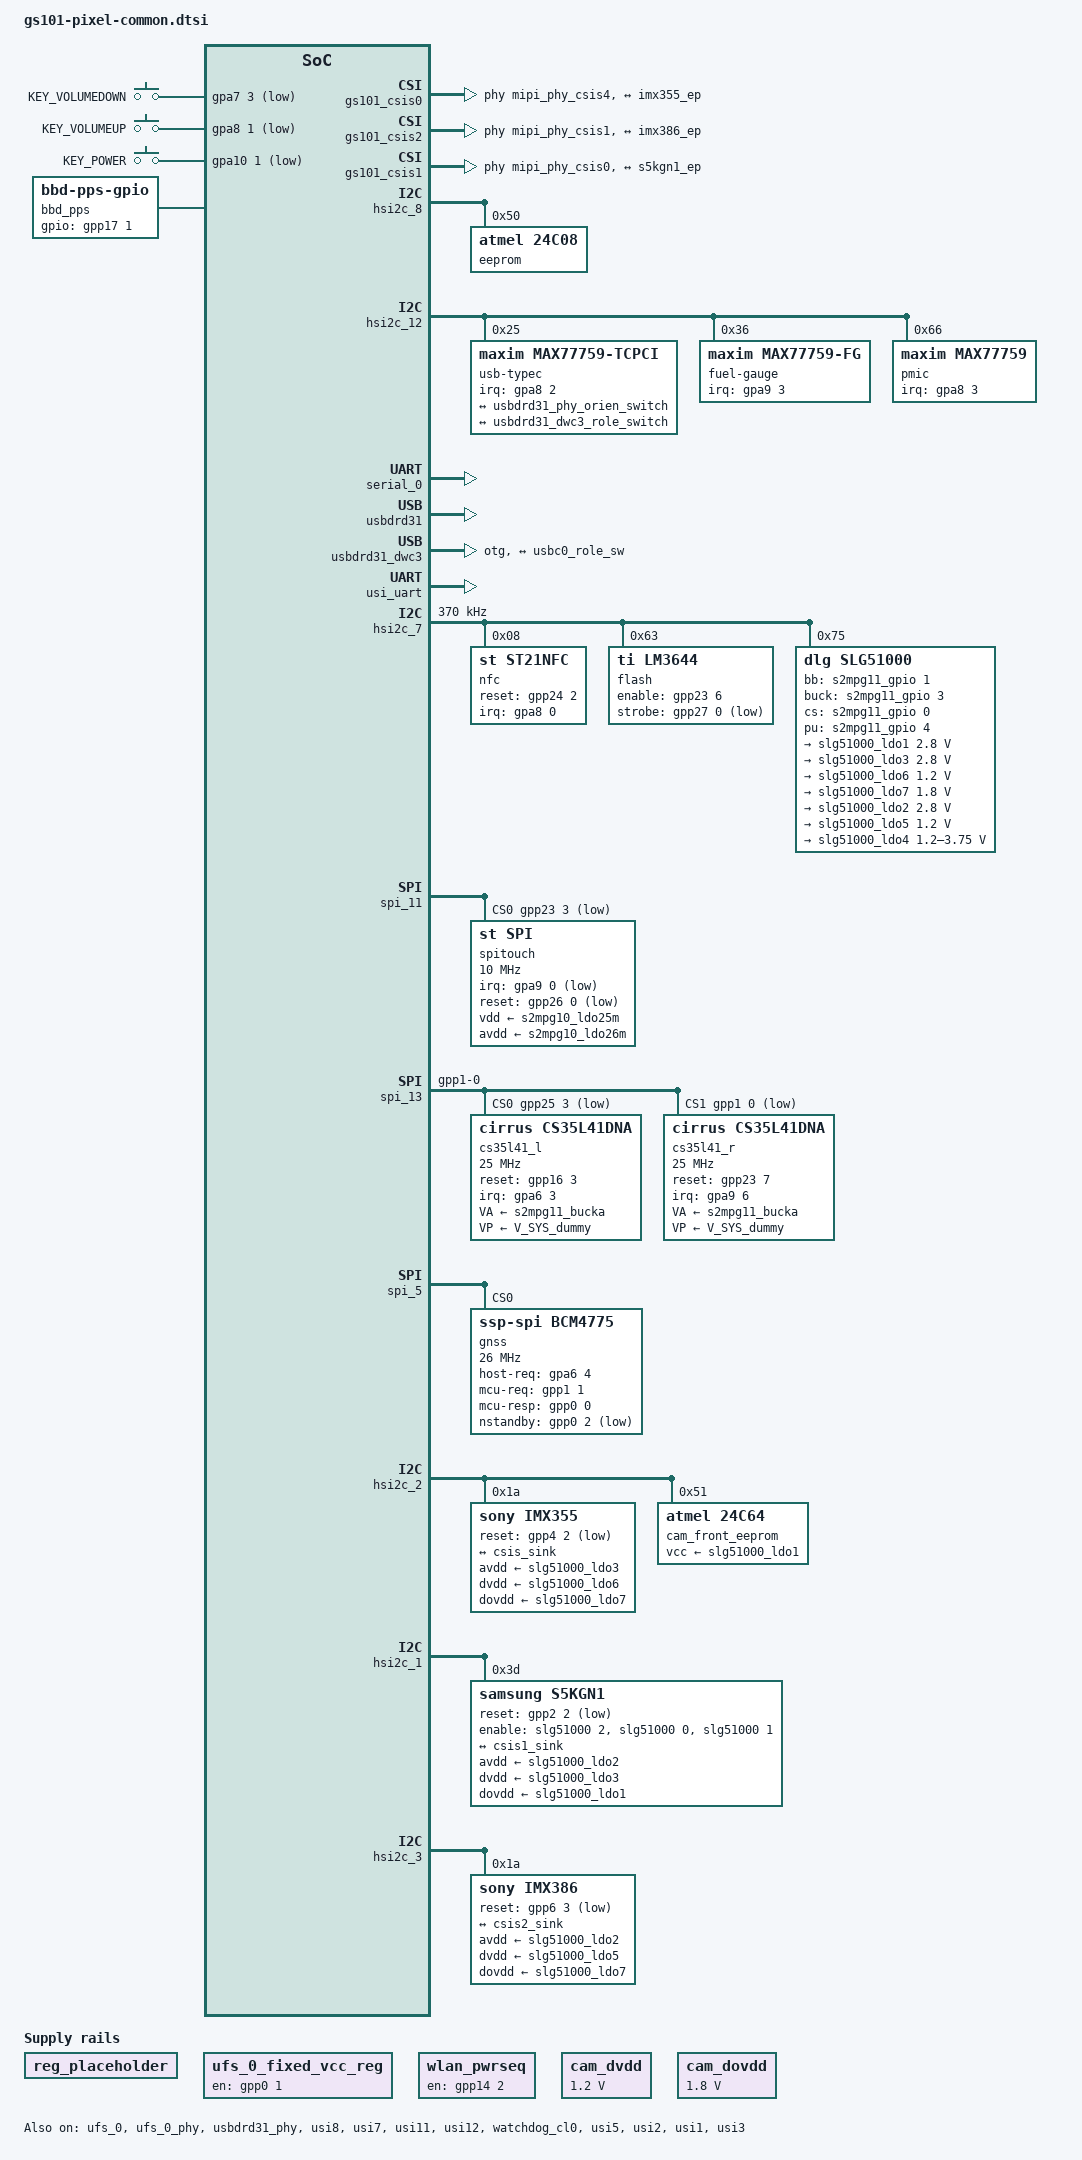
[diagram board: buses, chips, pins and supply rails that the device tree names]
// SPDX-License-Identifier: GPL-2.0-only
/*
 * Device Tree nodes common for all GS101-based Pixel
 *
 * Copyright 2021-2023 Google LLC
 * Copyright 2023 Linaro Ltd - <peter.griffin@linaro.org>
 */

/dts-v1/;

#include <dt-bindings/gpio/gpio.h>
#include <dt-bindings/input/input.h>
#include <dt-bindings/regulator/samsung,s2mpg10-regulator.h>
#include <dt-bindings/usb/pd.h>
#include "gs101-pinctrl.h"
#include "gs101.dtsi"
#include "gs101-audio.dtsi"
#include "gs101-cp-rmem.dtsi"
#include "gs101-cp-nodes.dtsi"
#include "gs101-cp-spi.dtsi"
#include <dt-bindings/media/video-interfaces.h>

/ {
	aliases {
		serial0 = &serial_0;
	};

	chosen {
		/* Bootloader expects bootargs specified otherwise it crashes */
		bootargs = "";
		stdout-path = &serial_0;

		/* Use display framebuffer as setup by bootloader */
		framebuffer0: framebuffer-0 {
			compatible = "simple-framebuffer";
			memory-region = <&cont_splash_mem>;
			vci-supply = <&s2mpg10_ldo22m>;
			vddi-supply = <&s2mpg11_bucka>;
			/* format properties to be added by actual board */
			status = "disabled";
		};
	};

	gpio-keys {
		compatible = "gpio-keys";
		pinctrl-0 = <&key_voldown>, <&key_volup>, <&key_power>;
		pinctrl-names = "default";

		button-vol-down {
			label = "KEY_VOLUMEDOWN";
			linux,code = <KEY_VOLUMEDOWN>;
			gpios = <&gpa7 3 GPIO_ACTIVE_LOW>;
			wakeup-source;
		};

		button-vol-up {
			label = "KEY_VOLUMEUP";
			linux,code = <KEY_VOLUMEUP>;
			gpios = <&gpa8 1 GPIO_ACTIVE_LOW>;
			wakeup-source;
		};

		button-power {
			label = "KEY_POWER";
			linux,code = <KEY_POWER>;
			gpios = <&gpa10 1 GPIO_ACTIVE_LOW>;
			wakeup-source;
		};
	};

	reboot-mode {
		compatible = "nvmem-reboot-mode";
		nvmem-cells = <&nvmem_reboot_mode>;
		nvmem-cell-names = "reboot-mode";
		mode-bootloader = <0x800000fc>;
		mode-charge = <0x8000000a>;
		mode-dm-verity-device-corrupted = <0x80000050>;
		mode-fastboot = <0x800000fa>;
		mode-reboot-ab-update = <0x80000052>;
		mode-recovery = <0x800000ff>;
		mode-rescue = <0x800000f9>;
		mode-shutdown-thermal = <0x80000051>;
		mode-shutdown-thermal-battery = <0x80000051>;
	};

	/* TODO: Remove this once PMIC is implemented  */
	reg_placeholder: regulator-0 {
		compatible = "regulator-fixed";
		regulator-name = "placeholder_reg";
	};

	/* TODO: Remove this once S2MPG11 slave PMIC is implemented  */
	ufs_0_fixed_vcc_reg: regulator-1 {
		compatible = "regulator-fixed";
		regulator-name = "ufs-vcc";
		gpio = <&gpp0 1 GPIO_ACTIVE_HIGH>;
		regulator-boot-on;
		enable-active-high;
	};

	/*
	 * WLAN power enable (BCM4389 on PCIe HSI2). The vendor "wl_reg_on"
	 * GPIO; drive it on so the endpoint is powered before the PCIe link
	 * trains. always-on because there is no bcmdhd driver to toggle it.
	 */
	wlan_pwrseq: regulator-wlan {
		compatible = "regulator-fixed";
		regulator-name = "wlan-en";
		gpio = <&gpp14 2 GPIO_ACTIVE_HIGH>;
		enable-active-high;
		regulator-always-on;
		regulator-boot-on;
	};

	/*
	 * Front camera (IMX355) digital/IO rails. On the vendor these are
	 * board rails that stay on; LWIS only toggles avdd (slg51000_ldo1).
	 * Modelled as always-on fixed regulators so the mainline imx355 driver
	 * (which requires avdd/dvdd/dovdd) can enable its bulk supplies.
	 * TODO(M1b): map to the real s2mpg rails feeding the sensor.
	 */
	cam_dvdd: regulator-cam-dvdd {
		compatible = "regulator-fixed";
		regulator-name = "cam-dvdd";
		regulator-min-microvolt = <1200000>;
		regulator-max-microvolt = <1200000>;
		regulator-always-on;
		regulator-boot-on;
	};

	cam_dovdd: regulator-cam-dovdd {
		compatible = "regulator-fixed";
		regulator-name = "cam-dovdd";
		regulator-min-microvolt = <1800000>;
		regulator-max-microvolt = <1800000>;
		regulator-always-on;
		regulator-boot-on;
	};

	/*
	 * Camera MIPI D/C-combo PHYs (samsung,mipi-phy-m0s4s4s4s4s4), one per
	 * CSIS link. Driven by phy-exynos-mipi-gs101; isolation via the gs101
	 * PMU syscon, reset via the CSIS sysreg. Consumed by the MIPI-CSIS
	 * receiver nodes (added with the CSIS driver, M-next). Addresses/reset
	 * bits from vendor gs101-isp.dtsi.
	 */
	sysreg_csis_reset: system-controller@1a420500 {
		compatible = "samsung,exynos-csis", "syscon";
		reg = <0x0 0x1A420500 0x8>;
	};

	mipi_phy_csis0: dcphy@1a4f1300 {
		compatible = "samsung,mipi-phy-m0s4s4s4s4s4";
		samsung,pmu-syscon = <&pmu_system_controller>;
		isolation = <0x3ebc>;
		samsung,reset-sysreg = <&sysreg_csis_reset>;
		reset = <0>;
		reg = <0x0 0x1A4F1300 0x500>;
		owner = <1>;
		#phy-cells = <1>;
	};

	mipi_phy_csis1: dcphy@1a4f1b00 {
		compatible = "samsung,mipi-phy-m0s4s4s4s4s4";
		samsung,pmu-syscon = <&pmu_system_controller>;
		isolation = <0x3ebc>;
		samsung,reset-sysreg = <&sysreg_csis_reset>;
		reset = <1>;
		reg = <0x0 0x1A4F1B00 0x500>;
		owner = <1>;
		#phy-cells = <1>;
	};

	mipi_phy_csis2: dcphy@1a4f2300 {
		compatible = "samsung,mipi-phy-m0s4s4s4s4s4";
		samsung,pmu-syscon = <&pmu_system_controller>;
		isolation = <0x3ebc>;
		samsung,reset-sysreg = <&sysreg_csis_reset>;
		reset = <2>;
		reg = <0x0 0x1A4F2300 0x300>;
		owner = <1>;
		#phy-cells = <1>;
	};

	mipi_phy_csis3: dcphy@1a4f2600 {
		compatible = "samsung,mipi-phy-m0s4s4s4s4s4";
		samsung,pmu-syscon = <&pmu_system_controller>;
		isolation = <0x3ebc>;
		samsung,reset-sysreg = <&sysreg_csis_reset>;
		reset = <3>;
		reg = <0x0 0x1A4F2600 0x300>;
		owner = <1>;
		#phy-cells = <1>;
	};

	/*
	 * dcphy4 is where the front IMX355 physically lands (proven 2026-09-18
	 * by probing every bank with the sensor streaming: only this one sees
	 * the HS clock). As a 4-lane receiver it uses the clock lane at 0x2B00
	 * and data lanes 0x2C00..0x2F00, i.e. the vendor DT's "csi4" (0x2B00,
	 * 0x300) plus "csi5" (0x2E00, 0x300) -- so the bank is 0x500 here and
	 * the separate csi5 node below is commented out (it would overlap).
	 */
	mipi_phy_csis4: dcphy@1a4f2b00 {
		compatible = "samsung,mipi-phy-m0s4s4s4s4s4";
		samsung,pmu-syscon = <&pmu_system_controller>;
		isolation = <0x3ebc>;
		samsung,reset-sysreg = <&sysreg_csis_reset>;
		reset = <4>;
		reg = <0x0 0x1A4F2B00 0x500>;	/* was 0x300 (vendor csi4 only) */
		owner = <1>;
		#phy-cells = <1>;
	};

/*	mipi_phy_csis5: dcphy@1a4f2e00 {	-- overlaps dcphy4's data lanes, see above
 *		compatible = "samsung,mipi-phy-m0s4s4s4s4s4";
 *		samsung,pmu-syscon = <&pmu_system_controller>;
 *		isolation = <0x3ebc>;
 *		samsung,reset-sysreg = <&sysreg_csis_reset>;
 *		reset = <5>;
 *		reg = <0x0 0x1A4F2E00 0x300>;
 *		owner = <1>;
 *		#phy-cells = <1>;
 *	};
 */

	mipi_phy_csis6: dcphy@1a4f3300 {
		compatible = "samsung,mipi-phy-m0s4s4s4s4s4";
		samsung,pmu-syscon = <&pmu_system_controller>;
		isolation = <0x3ebc>;
		samsung,reset-sysreg = <&sysreg_csis_reset>;
		reset = <6>;
		reg = <0x0 0x1A4F3300 0x300>;
		owner = <1>;
		#phy-cells = <1>;
	};

	mipi_phy_csis7: dcphy@1a4f3600 {
		compatible = "samsung,mipi-phy-m0s4s4s4s4s4";
		samsung,pmu-syscon = <&pmu_system_controller>;
		isolation = <0x3ebc>;
		samsung,reset-sysreg = <&sysreg_csis_reset>;
		reset = <7>;
		reg = <0x0 0x1A4F3600 0x300>;
		owner = <1>;
		#phy-cells = <1>;
	};

	/*
	 * MIPI-CSIS receivers (google,gs101-mipi-csis). Each gs101 CSIS link is
	 * separate hardware (link N = 0x1A440000 + N * 0x10000), so each is its
	 * own node/driver instance. They share the one CSIS write-DMA bank
	 * (0x1A4D0000, raw Bayer -> DRAM) but write through distinct virtual
	 * channels (google,csis-dma-vc). Register bases from vendor
	 * gs101-isp.dtsi (lwis_csi); the dcphys above are reached through the
	 * generic PHY framework, so the csis-phy bank is not mapped here.
	 *
	 * csis0: front camera IMX355 (4-lane) on link4 / dcphy4 / WDMA vc0.
	 * (Was link0 / dcphy0 until 2026-09-18 -- an unverified assumption;
	 * the sensor is wired to DCPHY4, see the dcphy4 node above.)
	 */
	gs101_csis0: mipi-csis@1a480000 {
		compatible = "google,gs101-mipi-csis";
		reg = <0x0 0x1A480000 0x1000>,   /* csis-link4 (was 0x1A440000 link0) */
		      <0x0 0x1A4D0000 0x10000>,  /* csis-dma (WDMA, shared) */
		      <0x0 0x1A4C0000 0x100>;    /* csis-ebuf (elastic buffer, shared) */
		reg-names = "csis-link4", "csis-dma", "csis-ebuf";
		/*
		 * reg[0] = link bank; IRQs are the WDMA frame-done for this vc
		 * (IRQ_CSIS_DMA0_CSIS = SPI 302) + the link IRQ (IRQ_CSIS4_CSIS
		 * = SPI 298; link0 was IRQ_CSIS0_CSIS = SPI 294), per vendor
		 * dt-bindings/.../gs101.h.
		 */
		interrupts = <GIC_SPI 302 IRQ_TYPE_LEVEL_HIGH 0>,
			     <GIC_SPI 298 IRQ_TYPE_LEVEL_HIGH 0>;
		interrupt-names = "csis-dma0", "csis-link4";
		/*
		 * CMU_CSIS leaf gates for this link + its WDMA context, from the
		 * generated cmu_csis block: APB bridge, CSIS core, WDMA, elastic
		 * buffer, this context's QoS engine, the D-PHY link wrapper, plus the
		 * ACPM CAM DVFS domain (stock LWIS votes 67 MHz at device enable).
		 */
		clocks = <&cmu_csis CLK_GOUT_CSIS_AD_APB_CSIS0_PCLKM>,
			 <&cmu_csis CLK_GOUT_CSIS_CSISX8_ACLK_C2_CSIS>,
			 <&cmu_csis CLK_GOUT_CSIS_CSISX8_ACLK_CSIS_DMA>,
			 <&cmu_csis CLK_GOUT_CSIS_CSISX8_ACLK_EBUF>,
			 <&cmu_csis CLK_GOUT_CSIS_QE_CSIS_DMA0_ACLK>,
			 <&cmu_csis CLK_GOUT_CSIS_QE_CSIS_DMA0_PCLK>,
			 <&cmu_csis CLK_GOUT_CSIS_MIPI_PHY_LINK_WRAP_ACLK_CSIS4>, /* was _CSIS0 */
			 <&acpm_ipc GS101_CLK_ACPM_DVFS_CAM>;
		clock-names = "apb", "c2", "dma", "ebuf", "qe-aclk", "qe-pclk",
			      "phy-wrap", "cam-dvfs";
		phys = <&mipi_phy_csis4 0>;	/* was <&mipi_phy_csis0 0> */
		/* imx355 full resolution; must match the sensor's default mode. */
		google,def-width = <3280>;
		google,def-height = <2464>;
		/*
		 * 2026-09-21: front stays on WDMA FMT 0x4 (U10BIT_PACK, SRGGB10P):
		 * the only layout measured with all 4 pixel bytes live (at 3280 px),
		 * and libcamera's quad-Bayer cell collapse (0008) takes the packed
		 * input only; with the driver default 6 (RG10) every front
		 * configuration was rejected ("No valid configuration found").
		 */
		/*
		 * 2026-09-22: 0x4 commented out (user decision, after the GBRG
		 * build was verified with wdma_fmt=0). With DBG_PIXEL_ALIGN_EN
		 * set, FMT 0x4 writes a dense LSB-first 10-bit bitstream, not
		 * the CSI2P layout, so every SRGGB10P reader saw every other
		 * pixel dead. The driver default 6 (16-bit unpacked, GB10 with
		 * leading-lines) is what plasma-camera and motion now use.
		 */
		/* google,wdma-fmt = <0x4>; */
		/*
		 * imx355 sends one embedded-data line (DT 0x12) on VC0 before
		 * the image; the link routes by VC only, so it lands as buffer
		 * line 0 and shifts the Bayer phase one row (RGGB -> GBRG).
		 * Proven with the sensor colour-bar test pattern 2026-09-22.
		 */
		google,leading-lines = <1>;
		/*
		 * SYSREG_CSIS: the WDMA input routing (stock HAL csi_context.cc:
		 * 0x430 + slot*4 = link, 0x408 + ctx*4 = slot, 0x488 enable bit
		 * link + ctx*8) and the per-PHY reset bits live here, not in the
		 * DMA context bank.
		 */
		samsung,sysreg = <&sysreg_csis>;
		memory-region = <&camera_cma>;
		google,csis-dma-vc = <0>;

		ports {
			#address-cells = <1>;
			#size-cells = <0>;

			/* sink from the front camera (IMX355) */
			port@0 {
				reg = <0>;
				csis_sink: endpoint {
					remote-endpoint = <&imx355_ep>;
					data-lanes = <1 2 3 4>;
				};
			};
		};
	};

	/*
	 * csis2: rear ultra-wide IMX386 (2-lane, on a 4-lane bank) on link1 / dcphy1 / WDMA vc1.
	 * Proven 2026-09-18 by probing every DCPHY bank with the sensor
	 * streaming: only dcphy1 (clock 0x1B00, data 0x1C00/0x1D00; the upper
	 * two lanes of that 4-lane bank stay idle) sees it. Was link2 / dcphy2
	 * (a 2-lane bank, chosen by assumption) until then. The node label
	 * stays gs101_csis2 so nothing else has to change.
	 */
	gs101_csis2: mipi-csis@1a450000 {
		compatible = "google,gs101-mipi-csis";
		reg = <0x0 0x1A450000 0x1000>,   /* csis-link1 (was 0x1A460000 link2) */
		      <0x0 0x1A4D0000 0x10000>,  /* csis-dma (WDMA, shared) */
		      <0x0 0x1A4C0000 0x100>;    /* csis-ebuf (elastic buffer, shared) */
		reg-names = "csis-link1", "csis-dma", "csis-ebuf";
		/* WDMA vc1 frame-done (IRQ_CSIS_DMA1_CSIS = SPI 303) + link1
		 * IRQ (IRQ_CSIS1_CSIS = SPI 295; link2 was IRQ_CSIS2_CSIS = 296).
		 */
		interrupts = <GIC_SPI 303 IRQ_TYPE_LEVEL_HIGH 0>,
			     <GIC_SPI 295 IRQ_TYPE_LEVEL_HIGH 0>;
		interrupt-names = "csis-dma1", "csis-link1";
		/*
		 * CMU_CSIS leaf gates for this link + its WDMA context, from the
		 * generated cmu_csis block: APB bridge, CSIS core, WDMA, elastic
		 * buffer, this context's QoS engine, the D-PHY link wrapper, plus the
		 * ACPM CAM DVFS domain (stock LWIS votes 67 MHz at device enable).
		 */
		clocks = <&cmu_csis CLK_GOUT_CSIS_AD_APB_CSIS0_PCLKM>,
			 <&cmu_csis CLK_GOUT_CSIS_CSISX8_ACLK_C2_CSIS>,
			 <&cmu_csis CLK_GOUT_CSIS_CSISX8_ACLK_CSIS_DMA>,
			 <&cmu_csis CLK_GOUT_CSIS_CSISX8_ACLK_EBUF>,
			 <&cmu_csis CLK_GOUT_CSIS_QE_CSIS_DMA1_ACLK>,
			 <&cmu_csis CLK_GOUT_CSIS_QE_CSIS_DMA1_PCLK>,
			 <&cmu_csis CLK_GOUT_CSIS_MIPI_PHY_LINK_WRAP_ACLK_CSIS1>, /* was _CSIS2 */
			 <&acpm_ipc GS101_CLK_ACPM_DVFS_CAM>;
		clock-names = "apb", "c2", "dma", "ebuf", "qe-aclk", "qe-pclk",
			      "phy-wrap", "cam-dvfs";
		phys = <&mipi_phy_csis1 0>;	/* was <&mipi_phy_csis2 0> */
		samsung,sysreg = <&sysreg_csis>;	/* WDMA routing + PHY reset, see csis0 */
		memory-region = <&camera_cma>;
		google,csis-dma-vc = <1>;
		/*
		 * WDMA FMT 0x1e (stock HAL value: 4 px in 5 bytes + 3 pad per 8):
		 * the dense SRGGB10P value never completes a 1920-px line on this
		 * link (2026-09-19). See the driver's wdma_fmt.
		 */
		/*
		 * 2026-09-21: 0x1e (S14BIT_UNPACK_MSB_ZERO) commented out so the
		 * rear takes the driver default 6 (U10BIT_UNPACK_MSB_ZERO, V4L2
		 * SRGGB10) like the front; same 16-bit-per-pixel DMA geometry.
		 */
		/* google,wdma-fmt = <0x1e>; */

		ports {
			#address-cells = <1>;
			#size-cells = <0>;

			/* sink from the rear ultra-wide camera (IMX386) */
			port@0 {
				reg = <0>;
				csis2_sink: endpoint {
					remote-endpoint = <&imx386_ep>;
					data-lanes = <1 2>;	/* see imx386_ep */
				};
			};
		};
	};

	/*
	 * csis1: rear main camera GN1 (4-lane) on WDMA vc2. Link/DCPHY bank NOT
	 * yet probed for this sensor (front = dcphy4, imx386 = dcphy1); link0 /
	 * dcphy0 is the first candidate (2026-09-21).
	 */
	gs101_csis1: mipi-csis@1a440000 {
		compatible = "google,gs101-mipi-csis";
		reg = <0x0 0x1A440000 0x1000>,   /* csis-link0 */
		      <0x0 0x1A4D0000 0x10000>,  /* csis-dma (WDMA, shared) */
		      <0x0 0x1A4C0000 0x100>;    /* csis-ebuf (elastic buffer, shared) */
		reg-names = "csis-link0", "csis-dma", "csis-ebuf";
		/* WDMA vc2 frame-done (IRQ_CSIS_DMA2_CSIS = SPI 304) + link0 IRQ
		 * (IRQ_CSIS0_CSIS = SPI 294).
		 */
		interrupts = <GIC_SPI 304 IRQ_TYPE_LEVEL_HIGH 0>,
			     <GIC_SPI 294 IRQ_TYPE_LEVEL_HIGH 0>;
		interrupt-names = "csis-dma2", "csis-link0";
		clocks = <&cmu_csis CLK_GOUT_CSIS_AD_APB_CSIS0_PCLKM>,
			 <&cmu_csis CLK_GOUT_CSIS_CSISX8_ACLK_C2_CSIS>,
			 <&cmu_csis CLK_GOUT_CSIS_CSISX8_ACLK_CSIS_DMA>,
			 <&cmu_csis CLK_GOUT_CSIS_CSISX8_ACLK_EBUF>,
			 <&cmu_csis CLK_GOUT_CSIS_QE_CSIS_DMA2_ACLK>,
			 <&cmu_csis CLK_GOUT_CSIS_QE_CSIS_DMA2_PCLK>,
			 <&cmu_csis CLK_GOUT_CSIS_MIPI_PHY_LINK_WRAP_ACLK_CSIS0>,
			 <&acpm_ipc GS101_CLK_ACPM_DVFS_CAM>;
		clock-names = "apb", "c2", "dma", "ebuf", "qe-aclk", "qe-pclk",
			      "phy-wrap", "cam-dvfs";
		phys = <&mipi_phy_csis0 0>;
		/* s5kgn1 default mode 4080x3072 (2x2 binned). */
		google,def-width = <4080>;
		google,def-height = <3072>;
		/* Packed RAW10 (SRGGB10P): 15.7 MB per frame instead of 25 MB unpacked. */
		google,wdma-fmt = <0x4>;
		samsung,sysreg = <&sysreg_csis>;
		memory-region = <&camera_cma>;
		google,csis-dma-vc = <2>;

		ports {
			#address-cells = <1>;
			#size-cells = <0>;

			/* sink from the rear main camera (GN1) */
			port@0 {
				reg = <0>;
				csis1_sink: endpoint {
					remote-endpoint = <&s5kgn1_ep>;
					/* GN1 is C-PHY, 3 trios (proven 2026-09-21: FRM_CNT + WDMA frames). */
					bus-type = <MEDIA_BUS_TYPE_CSI2_CPHY>;
					data-lanes = <1 2 3>;
					/* The driver reads the rate from its own sink endpoint (default 360 MHz). */
					link-frequencies = /bits/ 64 <798000000>;
				};
			};
		};
	};

	reserved-memory {
		cont_splash_mem: splash@fac00000 {
			/* size to be updated by actual board */
			reg = <0x0 0xfac00000 0x0>;
			no-map;
			status = "disabled";
		};

		/*
		 * Dedicated reusable CMA pool for the CSIS write-DMA buffers.
		 * A full imx355 frame is 3280x2464x2 ~16 MB; the shared 32 MB
		 * CMA cannot hand out that much contiguously once fragmented, so
		 * the two mipi-csis instances draw from this pool via their
		 * "memory-region" property. "reusable" lets the kernel use the
		 * area for movable pages until the camera actually claims it.
		 */
		/*
		 * Fixed placement (128 MiB @ 0xd0000000) in the large free gap
		 * between the AoC/TPU carveouts (end 0x97400000) and abl
		 * (0xf8800000). Dynamic placement (size/alloc-ranges) failed to
		 * reserve at boot here, leaving the device on the default 32 MiB
		 * CMA; a fixed reg is deterministic. Base and size are 4 MiB
		 * aligned (CMA_MIN_ALIGNMENT with ARCH_FORCE_MAX_ORDER=10).
		 */
		camera_cma: camera-cma@d0000000 {
			compatible = "shared-dma-pool";
			reusable;
			/* 2026-09-21: 256 MiB; three cameras, and 128 MiB fragmented into
			 * 29 MiB free with a 25 MiB GN1 frame -> dma_alloc -EBUSY.
			 */
			reg = <0x0 0xd0000000 0x10000000>;	/* 256 MiB (was 128) */
		};
	};
};

&acpm_ipc {
	pmic-1 {
		compatible = "samsung,s2mpg10-pmic";
		interrupts-extended = <&gpa0 6 IRQ_TYPE_LEVEL_LOW>;
		pinctrl-names = "default";
		pinctrl-0 = <&pmic_int>;
		system-power-controller;
		wakeup-source;

		vinl1m-supply = <&s2mpg11_buck3s>;
		vinl2m-supply = <&s2mpg11_buck3s>;
		vinl3m-supply = <&s2mpg10_buck8m>;
		vinl4m-supply = <&s2mpg10_buck9m>;
		vinl5m-supply = <&s2mpg10_buck9m>;
		vinl6m-supply = <&s2mpg10_buck9m>;
		vinl7m-supply = <&s2mpg11_buck6s>;
		vinl8m-supply = <&s2mpg11_buck6s>;
		vinl9m-supply = <&s2mpg11_buck7s>;
		vinl10m-supply = <&s2mpg11_buck7s>;
		vinl11m-supply = <&s2mpg11_buck7s>;
		vinl12m-supply = <&s2mpg11_bucka>;
		vinl13m-supply = <&s2mpg11_bucka>;
		vinl14m-supply = <&s2mpg11_buckboost>;
		vinl15m-supply = <&s2mpg11_buckboost>;

		clocks {
			compatible = "samsung,s2mpg10-clk";
			#clock-cells = <1>;
			clock-output-names = "rtc32k_ap", "peri32k1",
					     "peri32k2";
		};

		s2mpg10_gpio: s2mpg10-gpio {
			compatible = "samsung,s2mpg10-gpio";
			gpio-controller;
			#gpio-cells = <2>;
			ngpios = <6>;
		};

		regulators {
			buck1m {
				regulator-name = "vdd_mif";
				regulator-min-microvolt = <450000>;
				regulator-max-microvolt = <1300000>;
				regulator-ramp-delay = <6250>;
				regulator-always-on;
				samsung,ext-control = <S2MPG10_EXTCTRL_PWREN_MIF>;
			};

			buck2m {
				regulator-name = "vdd_cpucl2";
				regulator-min-microvolt = <450000>;
				regulator-max-microvolt = <1300000>;
				regulator-ramp-delay = <12500>;
				regulator-always-on;
				samsung,ext-control = <S2MPG10_EXTCTRL_CPUCL2_EN2>;
			};

			buck3m {
				regulator-name = "vdd_cpucl1";
				regulator-min-microvolt = <450000>;
				regulator-max-microvolt = <1300000>;
				regulator-ramp-delay = <12500>;
				regulator-always-on;
				samsung,ext-control = <S2MPG10_EXTCTRL_CPUCL1_EN2>;
			};

			buck4m {
				regulator-name = "vdd_cpucl0";
				regulator-min-microvolt = <450000>;
				regulator-max-microvolt = <1300000>;
				regulator-ramp-delay = <12500>;
				regulator-always-on;
				samsung,ext-control = <S2MPG10_EXTCTRL_PWREN>;
			};

			buck5m {
				regulator-name = "vdd_int";
				regulator-min-microvolt = <450000>;
				regulator-max-microvolt = <1300000>;
				regulator-ramp-delay = <12500>;
				regulator-always-on;
				samsung,ext-control = <S2MPG10_EXTCTRL_PWREN_MIF>;
			};

			buck6m {
				regulator-name = "vdd_cpucl2_m";
				regulator-min-microvolt = <450000>;
				regulator-max-microvolt = <1350000>;
				regulator-ramp-delay = <12500>;
				regulator-always-on;
				samsung,ext-control = <S2MPG10_EXTCTRL_CPUCL2_EN2>;
			};

			buck7m_reg: buck7m {
				/* GPU */
				regulator-name = "vdd_int_m";
				regulator-min-microvolt = <450000>;
				regulator-max-microvolt = <1300000>;
				regulator-ramp-delay = <6250>;
				regulator-always-on;
				samsung,ext-control = <S2MPG10_EXTCTRL_PWREN_MIF>;
			};

			s2mpg10_buck8m: buck8m {
				regulator-name = "lldo2";
				regulator-min-microvolt = <450000>;
				regulator-max-microvolt = <1300000>;
				regulator-ramp-delay = <6250>;
				// needs to be on during boot, until all consumers have
				// probed and established their links to this
				regulator-boot-on;
				/* Vendor gs101-pmic.dtsi: always-on (feeds an internal PMIC LDO group). */
				regulator-always-on;
			};

			s2mpg10_buck9m: buck9m {
				regulator-name = "lldo3";
				regulator-min-microvolt = <450000>;
				regulator-max-microvolt = <1300000>;
				regulator-ramp-delay = <6250>;
				// needs to be on during boot, until all consumers have
				// probed and established their links to this
				regulator-boot-on;
				/* Vendor gs101-pmic.dtsi: always-on (feeds an internal PMIC LDO group). */
				regulator-always-on;
			};

			buck10m {
				regulator-name = "vdd_tpu";
				regulator-min-microvolt = <450000>;
				regulator-max-microvolt = <1300000>;
				regulator-ramp-delay = <12500>;
				regulator-always-on;
				samsung,ext-control = <S2MPG10_EXTCTRL_TPU_EN>;
			};

			ldo1m {
				/* ALIVE, AOC PLL */
				regulator-name = "vdd_l1m_alive";
				regulator-min-microvolt = <700000>;
				regulator-max-microvolt = <1300000>;
				regulator-ramp-delay = <6250>;
				regulator-always-on;
			};

			ldo2m {
				/* lots, DDR */
				regulator-name = "vdd_l2m_alive";
				regulator-min-microvolt = <1600000>;
				regulator-max-microvolt = <1950000>;
				regulator-always-on;
			};

			ldo3m {
				/* AVDD: MIPI CSI & DSI, PLL: CPUCL SHARED TPU UFS */
				regulator-name = "ldo3m";
				regulator-min-microvolt = <725000>;
				regulator-max-microvolt = <1300000>;
				regulator-always-on;
				samsung,ext-control = <S2MPG10_EXTCTRL_PWREN_MIF>;
			};

			ldo4m {
				/* AVDD: MIPI CSI & DSI, UFS, OTP, TS_SUB, TS_TOP, XOTP */
				regulator-name = "ldo4m";
				regulator-min-microvolt = <1600000>;
				regulator-max-microvolt = <1950000>;
				regulator-always-on;
				samsung,ext-control = <S2MPG10_EXTCTRL_PWREN_MIF>;
			};

			ldo5m {
				/* VDD: ADD, AVDD: TCXO & TCXO_FAR */
				regulator-name = "avdd075_tcxo";
				regulator-min-microvolt = <725000>;
				regulator-max-microvolt = <1300000>;
				regulator-always-on;
				samsung,ext-control = <S2MPG10_EXTCTRL_TCXO_ON>;
			};

			ldo6m {
				/* PLL CPUCL & MIFx, UFS clk, MIPI DSI */
				regulator-name = "vdd_pll";
				regulator-min-microvolt = <725000>;
				regulator-max-microvolt = <1300000>;
				regulator-always-on;
				samsung,ext-control = <S2MPG10_EXTCTRL_PWREN_MIF>;
			};

			ldo7m {
				/* IO (HSI (USB)) */
				regulator-name = "vdd_hsi";
				regulator-min-microvolt = <450000>;
				regulator-max-microvolt = <950000>;
				regulator-ramp-delay = <6250>;
				/*
				 * TODO: link to HSI power domain, without this,
				 * Linux hangs during USB access.
				 */
				regulator-always-on;
			};

			ldo8m {
				regulator-name = "vdd085_usb";
				regulator-min-microvolt = <725000>;
				regulator-max-microvolt = <1300000>;
				regulator-always-on;
			};

			ldo9m {
				regulator-name = "vdd18_usb";
				regulator-min-microvolt = <1600000>;
				regulator-max-microvolt = <1950000>;
				regulator-always-on;
			};

			ldo10m {
				regulator-name = "vdd33_usb";
				regulator-min-microvolt = <1800000>;
				regulator-max-microvolt = <3350000>;
				regulator-always-on;
			};

			ldo11m {
				regulator-name = "vdd_cpucl1_m";
				regulator-min-microvolt = <700000>;
				regulator-max-microvolt = <1300000>;
				regulator-ramp-delay = <6250>;
				regulator-always-on;
				samsung,ext-control = <S2MPG10_EXTCTRL_CPUCL1_EN2>;
			};

			ldo12m {
				regulator-name = "vdd_cpucl0_m";
				regulator-min-microvolt = <700000>;
				regulator-max-microvolt = <1300000>;
				regulator-ramp-delay = <6250>;
				regulator-always-on;
				samsung,ext-control = <S2MPG10_EXTCTRL_PWREN>;
			};

			ldo13m {
				regulator-name = "vdd_tpu_m";
				regulator-min-microvolt = <450000>;
				regulator-max-microvolt = <950000>;
				regulator-ramp-delay = <12500>;
				regulator-always-on;
				samsung,ext-control = <S2MPG10_EXTCTRL_TPU_EN>;
			};

			/* ldo14m is board specific */

			ldo15m {
				regulator-name = "vdd_slc_m";
				regulator-min-microvolt = <450000>;
				regulator-max-microvolt = <950000>;
				regulator-ramp-delay = <12500>;
				regulator-always-on;
			};

			ldo16m {
				regulator-name = "vdd085_pcie0";
				regulator-min-microvolt = <725000>;
				regulator-max-microvolt = <1300000>;
			};

			ldo17m {
				regulator-name = "vdd085_pcie1";
				regulator-min-microvolt = <725000>;
				regulator-max-microvolt = <1300000>;
			};

			ldo18m {
				regulator-name = "vdd18_pcie0";
				regulator-min-microvolt = <1600000>;
				regulator-max-microvolt = <1950000>;
			};

			ldo19m {
				regulator-name = "vdd18_pcie1";
				regulator-min-microvolt = <1600000>;
				regulator-max-microvolt = <1950000>;
			};

			s2mpg10_ldo20m: ldo20m {
				/* DMIC, memory power */
				regulator-name = "vddq_aoc_pdm";
				regulator-min-microvolt = <1600000>;
				regulator-max-microvolt = <1950000>;
				regulator-always-on;
				samsung,ext-control = <S2MPG10_EXTCTRL_LDO20M_EN2>;
			};

			ldo21m {
				/* Dauntless  */
				regulator-name = "vdd_dtls";
				regulator-min-microvolt = <2500000>;
				regulator-max-microvolt = <3300000>;
				regulator-always-on;
			};

			s2mpg10_ldo22m: ldo22m {
				/* display */
				regulator-name = "vci_disp";
				regulator-min-microvolt = <3025000>;
				regulator-max-microvolt = <3025000>;
			};

			/* ldo23m & ldo24m are unused */

			s2mpg10_ldo25m: ldo25m {
				/* touch */
				regulator-name = "dvdd_tsp";
				regulator-min-microvolt = <1600000>;
				regulator-max-microvolt = <1950000>;
			};

			s2mpg10_ldo26m: ldo26m {
				/* touch */
				regulator-name = "avdd_ts";
				regulator-min-microvolt = <2500000>;
				regulator-max-microvolt = <3300000>;
			};

			ldo27m {
				/* under-display fingerprint scanner */
				regulator-name = "avdd_udfps";
				regulator-min-microvolt = <2500000>;
				regulator-max-microvolt = <3300000>;
			};

			/*
			 *ldo28m .. ldo30m are unused, ldo31m is board specific
			 */
		};
	};

	pmic-2 {
		compatible = "samsung,s2mpg11-pmic";
		interrupts-extended = <&gpa0 7 IRQ_TYPE_LEVEL_LOW>;
		pinctrl-names = "default";
		pinctrl-0 = <&sub_pmic_int>;
		wakeup-source;

		vinl1s-supply = <&s2mpg10_buck8m>;
		vinl2s-supply = <&s2mpg11_buck6s>;
		vinl3s-supply = <&s2mpg11_buck7s>;
		vinl4s-supply = <&s2mpg11_buck7s>;
		vinl5s-supply = <&s2mpg11_buckboost>;
		vinl6s-supply = <&s2mpg11_buckboost>;
		vinbd-supply = <&s2mpg11_buckboost>;

		s2mpg11_gpio: s2mpg11-gpio {
			compatible = "samsung,s2mpg11-gpio";
			gpio-controller;
			#gpio-cells = <2>;
			ngpios = <6>;

			/*
			 * pu/buck/bb are the SLG51000 camera-PMIC master
			 * enables. They are NOT hogged here any more: the
			 * slg51000 driver now owns them (dlg,pu/buck/bb-gpios)
			 * and drives them in the required order at probe
			 * (bb -> buck -> cs -> pu). Hogging them output-high at
			 * DT-parse asserted pu before cs, which left the buck/
			 * buck-boost-fed LDOs (ldo5/6/7 = cam dvdd/dovdd)
			 * un-armed, so the sensors NACK'd on I2C (-EIO).
			 *
			 * slg51000_pu_hog {
			 *	gpio-hog;
			 *	gpios = <4 GPIO_ACTIVE_HIGH>;
			 *	output-high;
			 *	line-name = "slg51000_pu";
			 * };
			 * slg51000_buck_hog {
			 *	gpio-hog;
			 *	gpios = <3 GPIO_ACTIVE_HIGH>;
			 *	output-high;
			 *	line-name = "slg51000_buck";
			 * };
			 * slg51000_bb_hog {
			 *	gpio-hog;
			 *	gpios = <1 GPIO_ACTIVE_HIGH>;
			 *	output-high;
			 *	line-name = "slg51000_bb";
			 * };
			 */
		};

		regulators {
			buck1s {
				/* multimedia */
				regulator-name = "vdd_cam";
				regulator-min-microvolt = <450000>;
				regulator-max-microvolt = <1300000>;
				regulator-ramp-delay = <12500>;
				regulator-always-on;
				samsung,ext-control = <S2MPG11_EXTCTRL_PWREN_MIF>;
			};

			buck2s_reg: buck2s {
				regulator-name = "vdd_g3d";
				regulator-min-microvolt = <450000>;
				regulator-max-microvolt = <1300000>;
				regulator-ramp-delay = <12500>;
				regulator-always-on;
				samsung,ext-control = <S2MPG11_EXTCTRL_G3D_EN>;
			};

			s2mpg11_buck3s: buck3s {
				regulator-name = "lldo1";
				regulator-min-microvolt = <450000>;
				regulator-max-microvolt = <1300000>;
				regulator-ramp-delay = <6250>;
				/* Vendor gs101-pmic.dtsi: always-on (feeds an internal PMIC LDO group). */
				regulator-always-on;
			};

			buck4s {
				/* DDR */
				regulator-name = "vdd2h_mem";
				regulator-min-microvolt = <450000>;
				regulator-max-microvolt = <1300000>;
				regulator-ramp-delay = <6250>;
				regulator-always-on;
			};

			buck5s {
				/* DDR */
				regulator-name = "vddq_mem";
				regulator-min-microvolt = <400000>;
				regulator-max-microvolt = <1300000>;
				regulator-ramp-delay = <6250>;
				regulator-always-on;
				samsung,ext-control = <S2MPG11_EXTCTRL_PWREN_MIF>;
			};

			s2mpg11_buck6s: buck6s {
				regulator-name = "lldo4";
				regulator-min-microvolt = <1000000>;
				regulator-max-microvolt = <1500000>;
				regulator-ramp-delay = <6250>;
				/* Vendor gs101-pmic.dtsi: always-on (feeds an internal PMIC LDO group). */
				regulator-always-on;
			};

			s2mpg11_buck7s: buck7s {
				regulator-name = "mldo";
				regulator-min-microvolt = <1500000>;
				regulator-max-microvolt = <2200000>;
				regulator-ramp-delay = <6250>;
				/* Vendor gs101-pmic.dtsi: always-on (feeds an internal PMIC LDO group). */
				regulator-always-on;
			};

			buck8s_reg: buck8s {
				regulator-name = "vdd_g3d_l2";
				regulator-min-microvolt = <450000>;
				regulator-max-microvolt = <1300000>;
				regulator-ramp-delay = <12500>;
				regulator-always-on;
				samsung,ext-control = <S2MPG11_EXTCTRL_G3D_EN>;
			};

			buck9s {
				regulator-name = "vdd_aoc";
				regulator-min-microvolt = <450000>;
				regulator-max-microvolt = <1300000>;
				regulator-ramp-delay = <12500>;
				regulator-always-on;
			};

			buck10s {
				/* DDR */
				regulator-name = "vdd2l_mem";
				regulator-min-microvolt = <450000>;
				regulator-max-microvolt = <1300000>;
				regulator-ramp-delay = <6250>;
				regulator-always-on;
			};

			buckd {
				regulator-name = "vcc_ufs";
				regulator-min-microvolt = <2400000>;
				regulator-max-microvolt = <3300000>;
				regulator-ramp-delay = <6250>;
				regulator-always-on;
				samsung,ext-control = <S2MPG11_EXTCTRL_UFS_EN>;
			};

			s2mpg11_bucka: bucka {
				/* lots, IO */
				regulator-name = "bucka";
				regulator-min-microvolt = <1700000>;
				regulator-max-microvolt = <2100000>;
				regulator-ramp-delay = <6250>;
				regulator-always-on;
			};

			s2mpg11_buckboost: buckboost {
				regulator-name = "buckboost";
				regulator-min-microvolt = <3000000>;
				regulator-max-microvolt = <3600000>;
			};

			ldo1s_reg: ldo1s {
				regulator-name = "vdd_g3d_m";
				regulator-min-microvolt = <450000>;
				regulator-max-microvolt = <950000>;
				regulator-ramp-delay = <6250>;
				regulator-always-on;
				samsung,ext-control = <S2MPG11_EXTCTRL_G3D_EN>;
			};

			ldo2s {
				regulator-name = "vdd_aoc_ret";
				regulator-min-microvolt = <450000>;
				regulator-max-microvolt = <950000>;
				regulator-ramp-delay = <12500>;
				regulator-always-on;
			};

			/* ldo3s & ldo5s are unused, ldo4s is board specific */

			s2mpg11_ldo6s: ldo6s {
				/* sensors */
				regulator-name = "vdd_prox";
				regulator-min-microvolt = <2500000>;
				regulator-max-microvolt = <3300000>;
			};

			s2mpg11_ldo7s: ldo7s {
				/* sensors */
				regulator-name = "vdd_sensors";
				regulator-min-microvolt = <1600000>;
				regulator-max-microvolt = <1950000>;
			};

			ldo8s {
				regulator-name = "vccq_ufs";
				regulator-min-microvolt = <1130400>;
				regulator-max-microvolt = <1281200>;
				regulator-always-on;
				samsung,ext-control = <S2MPG11_EXTCTRL_UFS_EN>;
			};

			ldo9s {
				regulator-name = "vdd_gnss";
				regulator-min-microvolt = <725000>;
				regulator-max-microvolt = <1300000>;
			};

			ldo10s {
				regulator-name = "vdd_gnss_rf";
				regulator-min-microvolt = <1600000>;
				regulator-max-microvolt = <1950000>;
			};

			ldo11s {
				regulator-name = "vdd_gnss_aux";
				regulator-min-microvolt = <1600000>;
				regulator-max-microvolt = <1950000>;
			};

			/* ldo12s is unused */

			ldo13s {
				regulator-name = "vddq_mmc";
				regulator-min-microvolt = <1800000>;
				regulator-max-microvolt = <3350000>;
				regulator-always-on;
				samsung,ext-control = <S2MPG11_EXTCTRL_LDO13S_EN>;
			};

			/* ldo14s is board specific, ldo15s is unused */
		};
	};
};

&ext_24_5m {
	clock-frequency = <24576000>;
};

&ext_200m {
	clock-frequency = <200000000>;
};

&hsi2c_8 {
	status = "okay";

	eeprom: eeprom@50 {
		compatible = "atmel,24c08";
		reg = <0x50>;
	};
};

&gpu {
     mali-supply = <&buck2s_reg>;
     buck8s-supply = <&buck8s_reg>;
     ldo1s-supply = <&ldo1s_reg>;
     buck7m-supply = <&buck7m_reg>;
};

&hsi2c_12 {
	status = "okay";
	/* TODO: add the devices once drivers exist */

	usb-typec@25 {
		compatible = "maxim,max77759-tcpci", "maxim,max33359";
		reg = <0x25>;
		interrupts-extended = <&gpa8 2 IRQ_TYPE_LEVEL_LOW>;
		pinctrl-0 = <&typec_int>;
		pinctrl-names = "default";

		connector {
			compatible = "usb-c-connector";
			label = "USB-C";
			data-role = "dual";
			power-role = "dual";
			self-powered;
			try-power-role = "sink";
			op-sink-microwatt = <2600000>;
			slow-charger-loop;
			/*
			 * max77759 operating in reverse boost mode (0xA) can
			 * source up to 1.5A while extboost can only do ~1A.
			 * Since extboost is the primary path, advertise 900mA.
			 */
			source-pdos = <PDO_FIXED(5000, 900,
						 (PDO_FIXED_SUSPEND
						  | PDO_FIXED_USB_COMM
						  | PDO_FIXED_DATA_SWAP
						  | PDO_FIXED_DUAL_ROLE))>;
			sink-pdos = <PDO_FIXED(5000, 3000,
					       (PDO_FIXED_DATA_SWAP
						| PDO_FIXED_USB_COMM
						| PDO_FIXED_HIGHER_CAP
						| PDO_FIXED_DUAL_ROLE))
				     PDO_FIXED(9000, 2200, 0)
				     PDO_PPS_APDO(5000, 11000, 3000)>;
			sink-vdos = <VDO_IDH(1, 1, IDH_PTYPE_PERIPH, 0,
					     IDH_PTYPE_DFP_HOST, 2, 0x18d1)
				     VDO_CERT(0x0)
				     VDO_PRODUCT(0x4ee1, 0x0)
				     VDO_UFP(UFP_VDO_VER1_2,
					     (DEV_USB2_CAPABLE
					      | DEV_USB3_CAPABLE),
					     UFP_RECEPTACLE, 0,
					     AMA_VCONN_NOT_REQ, 0,
					     UFP_ALTMODE_NOT_SUPP,
					     UFP_USB32_GEN1)
				     /* padding */ 0
				     VDO_DFP(DFP_VDO_VER1_1,
					     (HOST_USB2_CAPABLE
					      | HOST_USB3_CAPABLE),
					     DFP_RECEPTACLE, 0)>;
			sink-vdos-v1 = <VDO_IDH(1, 1, IDH_PTYPE_PERIPH, 0,
						0, 0, 0x18d1)
					VDO_CERT(0x0)
					VDO_PRODUCT(0x4ee1, 0x0)>;
			/*
			 * Until bootloader is updated to set those two when
			 * console is enabled, we disable PD here.
			 */
			pd-disable;
			typec-power-opmode = "default";

			ports {
				#address-cells = <1>;
				#size-cells = <0>;

				port@0 {
					reg = <0>;

					usbc0_orien_sw: endpoint {
						remote-endpoint = <&usbdrd31_phy_orien_switch>;
					};
				};

				port@1 {
					reg = <1>;

					usbc0_role_sw: endpoint {
						remote-endpoint = <&usbdrd31_dwc3_role_switch>;
					};
				};
			};
		};
	};

	fuel-gauge@36 {
		compatible = "maxim,max77759-fg";
		reg = <0x36>;

		pinctrl-0 = <&if_pmic_fg_int>;
		pinctrl-names = "default";
		interrupts-extended = <&gpa9 3 IRQ_TYPE_LEVEL_LOW>;

		shunt-resistor-micro-ohms = <5000>;
	};

	pmic@66 {
		compatible = "maxim,max77759";
		reg = <0x66>;

		pinctrl-0 = <&if_pmic_int>;
		pinctrl-names = "default";
		interrupts-extended = <&gpa8 3 IRQ_TYPE_LEVEL_LOW>;

		interrupt-controller;
		#interrupt-cells = <2>;

		gpio {
			compatible = "maxim,max77759-gpio";

			gpio-controller;
			#gpio-cells = <2>;
			/*
			 * "Human-readable name [SIGNAL_LABEL]" where the
			 * latter comes from the schematic
			 */
			gpio-line-names = "OTG boost [OTG_BOOST_EN]",
					  "max20339 IRQ [MW_OVP_INT_L]";

			interrupt-controller;
			#interrupt-cells = <2>;
		};

		nvmem-0 {
			compatible = "maxim,max77759-nvmem";

			nvmem-layout {
				compatible = "fixed-layout";
				#address-cells = <1>;
				#size-cells = <1>;

				nvmem_reboot_mode: reboot-mode@0 {
					reg = <0x0 0x4>;
				};

				boot-reason@4 {
					reg = <0x4 0x4>;
				};

				shutdown-user-flag@8 {
					reg = <0x8 0x1>;
				};

				rsoc@a {
					reg = <0xa 0x2>;
				};
			};
		};
	};
};

&pinctrl_far_alive {
	/*
	 * gpa8 belongs to this controller, not pinctrl_gpio_alive where this
	 * node used to sit. Declared there, the group was never registered
	 * ("174d0000.pinctrl: does not have pin group gpa8-6") and the AoC
	 * interrupt line was left unconfigured.
	 */
	aoc2ap_irq: aoc2ap-irq {
		samsung,pins = "gpa8-6";
		samsung,pin-function = <GS101_PIN_FUNC_EINT>;
		samsung,pin-pud = <GS101_PIN_PULL_DOWN>;
		samsung,pin-drv = <GS101_PIN_DRV_2_5_MA>;
	};

	key_voldown: key-voldown-pins {
		samsung,pins = "gpa7-3";
		samsung,pin-function = <GS101_PIN_FUNC_EINT>;
		samsung,pin-pud = <GS101_PIN_PULL_NONE>;
		samsung,pin-drv = <GS101_PIN_DRV_2_5_MA>;
	};

	key_volup: key-volup-pins {
		samsung,pins = "gpa8-1";
		samsung,pin-function = <GS101_PIN_FUNC_EINT>;
		samsung,pin-pud = <GS101_PIN_PULL_NONE>;
		samsung,pin-drv = <GS101_PIN_DRV_2_5_MA>;
	};

	typec_int: typec-int-pins {
		samsung,pins = "gpa8-2";
		samsung,pin-function = <GS101_PIN_FUNC_EINT>;
		samsung,pin-pud = <GS101_PIN_PULL_UP>;
		samsung,pin-drv = <GS101_PIN_DRV_2_5_MA>;
	};

	if_pmic_int: if-pmic-int-pins {
		samsung,pins = "gpa8-3";
		samsung,pin-function = <GS101_PIN_FUNC_EINT>;
		samsung,pin-pud = <GS101_PIN_PULL_UP>;
		samsung,pin-drv = <GS101_PIN_DRV_2_5_MA>;
	};
};

&pinctrl_gpio_alive {
	pmic_int: pmic-int-pins {
		samsung,pins = "gpa0-6";
		samsung,pin-function = <GS101_PIN_FUNC_EINT>;
		samsung,pin-pud = <GS101_PIN_PULL_NONE>;
	};

	sub_pmic_int: sub-pmic-int-pins {
		samsung,pins = "gpa0-7";
		samsung,pin-function = <GS101_PIN_FUNC_EINT>;
		samsung,pin-pud = <GS101_PIN_PULL_NONE>;
	};

	if_pmic_fg_int: if-pmic-fg-int-pins {
		samsung,pins = "gpa9-3";
		samsung,pin-function = <GS101_PIN_FUNC_EINT>;
		samsung,pin-pud = <GS101_PIN_PULL_UP>;
		samsung,pin-drv = <GS101_PIN_DRV_2_5_MA>;
	};

	key_power: key-power-pins {
		samsung,pins = "gpa10-1";
		samsung,pin-function = <GS101_PIN_FUNC_EINT>;
		samsung,pin-pud = <GS101_PIN_PULL_NONE>;
		samsung,pin-drv = <GS101_PIN_DRV_2_5_MA>;
	};
	ts_irq: ts-irq {
		samsung,pins = "gpa9-0";
		samsung,pin-function = <GS101_PIN_FUNC_EINT>;
		samsung,pin-pud = <GS101_PIN_PULL_NONE>;
		samsung,pin-drv = <GS101_PIN_DRV_2_5_MA>;
	};
};

&pinctrl_peric1 {
	ts_reset: ts-reset {
		samsung,pins = "gpp26-0";
		samsung,pin-pud = <GS101_PIN_PULL_NONE>;
		samsung,pin-con-pdn = <GS101_PIN_PDN_PREV>;
		samsung,pin-pud-pdn = <GS101_PIN_PULL_NONE>;
	};
	ap2aoc: ap2aoc {
		samsung,pins = "gpp26-1";
		samsung,pin-pud = <GS101_PIN_PULL_NONE>;
		samsung,pin-con-pdn = <GS101_PIN_PDN_PREV>;
		samsung,pin-pud-pdn = <GS101_PIN_PULL_NONE>;
	};
};

&serial_0 {
	status = "okay";
};

&ufs_0 {
	status = "okay";
	vcc-supply = <&ufs_0_fixed_vcc_reg>;
};

&ufs_0_phy {
	status = "okay";
};

&usbdrd31 {
	vdd10-supply = <&reg_placeholder>;
	vdd33-supply = <&reg_placeholder>;
	status = "okay";
};

&usbdrd31_dwc3 {
	dr_mode = "otg";
	usb-role-switch;
	role-switch-default-mode = "peripheral";
	maximum-speed = "super-speed-plus";
	status = "okay";

	port {
		usbdrd31_dwc3_role_switch: endpoint {
			remote-endpoint = <&usbc0_role_sw>;
		};
	};
};

&usbdrd31_phy {
	orientation-switch;
	/* TODO: Update these once PMIC is implemented */
	pll-supply = <&reg_placeholder>;
	dvdd-usb20-supply = <&reg_placeholder>;
	vddh-usb20-supply = <&reg_placeholder>;
	vdd33-usb20-supply = <&reg_placeholder>;
	vdda-usbdp-supply = <&reg_placeholder>;
	vddh-usbdp-supply = <&reg_placeholder>;
	status = "okay";

	port {
		usbdrd31_phy_orien_switch: endpoint {
			remote-endpoint = <&usbc0_orien_sw>;
		};
	};
};

&usi_uart {
	samsung,clkreq-on; /* needed for UART mode */
	status = "okay";
};

&usi8 {
	samsung,mode = <USI_MODE_I2C>;
	status = "okay";
};

&usi7 {
	samsung,mode = <USI_MODE_I2C>;
	status = "okay";
};

&usi11 {
	samsung,mode = <USI_MODE_SPI>;
	status = "okay";
};

&usi12 {
	samsung,mode = <USI_MODE_I2C>;
	status = "okay";
};

/*
 * NFC. The silicon is an ST54J (an ST21NFC controller with an embedded secure
 * element); it binds "st,st21nfc" all the same. The vendor drives it with its
 * own driver and extra properties -- a PMU reference clock, a clock-request
 * line, a power-idle line (gs101-whitefin-nfc.dtsi). Those turned out not to
 * be needed: with just the reset GPIO the chip talks NCI and reports its full
 * protocol set (Felica, MIFARE, Jewel, ISO-DEP, NFC-DEP, ISO-15693).
 *
 * What does not work is nfc_dev_up, which fails at secure-element discovery:
 * st_nci_hci_network_init floods proprietary notifications (opcode 0xe3e) and
 * times out. That path is only for the SE, whose protocol is Google's own, so
 * st_nci_discover_se() is patched to skip it when no SE is declared here --
 * which is why this node declares none. Reader and host-card-emulation are
 * pure NCI and do not need the SE.
 */
&hsi2c_7 {
	#address-cells = <1>;
	#size-cells = <0>;
	clock-frequency = <370000>;
	status = "okay";

	nfc@8 {
		compatible = "st,st21nfc";
		reg = <0x08>;

		interrupt-parent = <&gpa8>;
		interrupts = <0 IRQ_TYPE_LEVEL_HIGH>;
		reset-gpios = <&gpp24 2 GPIO_ACTIVE_HIGH>;
	};

	/*
	 * LM3644 dual-LED camera flash (rear). Vendor drives it via its own
	 * LWIS framework ("google,lwis-i2c-device"); mainline binds the TI
	 * V4L2 flash subdev instead. Wiring from gs101 RE:
	 *   HW enable  = gpp23[6], active-high (AP2FLASH_EN)
	 *   ext strobe = gpp27[0], active-low  (optional; SW strobe over I2C
	 *                works without it)
	 * The front camera (imx355) has no LED flash.
	 */
	flash@63 {
		compatible = "ti,lm3644";
		reg = <0x63>;

		enable-gpios = <&gpp23 6 GPIO_ACTIVE_HIGH>;
		strobe-gpios = <&gpp27 0 GPIO_ACTIVE_LOW>;
	};

	/*
	 * SLG51000 camera-side PMIC. The driver powers the chip up by
	 * driving the four master-enable lines in order at probe
	 * (bb -> buck -> cs -> pu), matching the vendor camera-pmic DT.
	 * Also supplies the VL53L1 ToF sensor's VIO from ldo1.
	 */
	slg51000: pmic@75 {
		compatible = "dlg,slg51000";
		reg = <0x75>;
		dlg,bb-gpios = <&s2mpg11_gpio 1 GPIO_ACTIVE_HIGH>;
		dlg,buck-gpios = <&s2mpg11_gpio 3 GPIO_ACTIVE_HIGH>;
		dlg,cs-gpios = <&s2mpg11_gpio 0 GPIO_ACTIVE_HIGH>;
		dlg,pu-gpios = <&s2mpg11_gpio 4 GPIO_ACTIVE_HIGH>;
		/* GPIO1..4 outputs: rear main camera (GN1) module enables. */
		gpio-controller;
		#gpio-cells = <2>;

		regulators {
			/*
			 * 2026-09-21: the "bias pairing" below is the production
			 * OTP mux (regmap 0x1715..0x171b = 03 05 2c 04 05 2d 02):
			 * enable bit0 -> LDO7, bit1 -> LDO1, bit2 -> LDO4,
			 * bit3 -> LDO2+LDO5, bit4 -> LUT -> LDO6, bit6 -> GPIO4.
			 * So "ldoN" here switches a different physical LDO than
			 * its name; VSEL registers are still per physical LDO.
			 * Verified with i2ctransfer on MATRIX_CONF_A (0x110d).
			 */
			/*
			 * SLG51000 LDO bias pairing (found empirically on the
			 * device): an LDO only reaches VOUT_OK if its bias
			 * companion is also enabled -
			 *   ldo7 <- ldo1,  ldo6 <- ldo5,  ldo2/ldo5 <- ldo4.
			 * ldo3 stands alone. So ldo1, ldo4 and ldo5 are marked
			 * always-on: they are the companions that let the sensor
			 * rails (ldo3/6/7 for imx355, ldo2/5/7 for imx386) come
			 * up. Without them the sensor gets avdd but no dvdd/
			 * dovdd -> I2C tx timeout / -EIO. A companion only needs
			 * to be *enabled* to provide bias; it need not itself
			 * regulate.
			 *
			 * ldo1 = front-cam EEPROM (m24c64s @0x51) + bias for ldo7.
			 */
			slg51000_ldo1: ldo1 {
				regulator-name = "slg51000_ldo1";
				regulator-min-microvolt = <2800000>;
				regulator-max-microvolt = <2800000>;
				regulator-always-on;
				regulator-boot-on;
			};

			/*
			 * IMX355 front camera rails:
			 *   ldo3 = avdd  2.8 V   (reg-init 0x2300 = 0xA0)
			 *   ldo6 = dvdd  1.2 V   (reg-init 0x2900 = 0xA0)
			 *   ldo7 = dovdd 1.8 V   (reg 0x3100, HW default)
			 */
			slg51000_ldo3: ldo3 {
				regulator-name = "slg51000_ldo3";
				regulator-min-microvolt = <2800000>;
				regulator-max-microvolt = <2800000>;
			};

			slg51000_ldo6: ldo6 {
				regulator-name = "slg51000_ldo6";
				regulator-min-microvolt = <1200000>;
				regulator-max-microvolt = <1200000>;
			};

			slg51000_ldo7: ldo7 {
				regulator-name = "slg51000_ldo7";
				regulator-min-microvolt = <1800000>;
				regulator-max-microvolt = <1800000>;
			};

			/*
			 * IMX386 rear ultra-wide rails (proto1 wiring):
			 *   ldo2 = avdd 2.8 V, ldo5 = dvdd 1.2 V, ldo7 = dovdd (shared)
			 */
			slg51000_ldo2: ldo2 {
				regulator-name = "slg51000_ldo2";
				regulator-min-microvolt = <2800000>;
				regulator-max-microvolt = <2800000>;
			};

			slg51000_ldo5: ldo5 {
				regulator-name = "slg51000_ldo5";
				regulator-min-microvolt = <1200000>;
				regulator-max-microvolt = <1200000>;
				/* dvdd for imx386; also bias companion for ldo6 */
				regulator-always-on;
				regulator-boot-on;
			};

			/*
			 * Vendor proto1 DT: ldo4 is the GN1 (rear main camera)
			 * dvdd, with ldo1 = avdd and ldo7 = dovdd (2026-09-21).
			 */
			/*
			 * ldo4 is not wired to a sensor rail, but it is the bias
			 * companion that lets ldo2 (imx386 avdd) and ldo5 reach
			 * VOUT_OK. Kept always-on for that; voltage left at its
			 * hardware default (wide range, no clamp).
			 */
			slg51000_ldo4: ldo4 {
				regulator-name = "slg51000_ldo4";
				regulator-min-microvolt = <1200000>;
				regulator-max-microvolt = <3750000>;
				regulator-always-on;
				regulator-boot-on;
			};
		};
	};
};

&watchdog_cl0 {
	timeout-sec = <30>;
	status = "okay";
};

&spi_11 {
	#address-cells = <1>;
	#size-cells = <0>;
	status = "okay";
	pinctrl-0 = <>;
	cs-gpios = <&gpp23 3 GPIO_ACTIVE_LOW>;
	num-cs = <1>;
	spitouch: touchscreen@0 {
		compatible = "st,spi";
		status = "okay";
		spi-max-frequency = <10000000>;
		reg = <0>;
		pinctrl-names = "pmx_ts_active", "pmx_ts_suspend";
		pinctrl-0 = <&ts_irq &ts_reset &ap2aoc &aoc2ap_irq
			     &spi11_bus &spi11_cs>;
		pinctrl-1 = <&ts_irq &ts_reset &ap2aoc &aoc2ap_irq
			     &spi11_bus &spi11_cs>;
		fts,irq-gpio = <&gpa9 0 GPIO_ACTIVE_LOW>;
		fts,irq-flags = <0x2008>; /* IRQF_TRIGGER_LOW | IRQF_ONESHOT */
		fts,reset-gpio-enable;
		fts,reset-gpio = <&gpp26 0 GPIO_ACTIVE_LOW>;
		fts,bus-reg-name = "vdd";
		fts,pwr-reg-name = "avdd";
		vdd-supply = <&s2mpg10_ldo25m>;
		avdd-supply = <&s2mpg10_ldo26m>;
		controller-data {
			samsung,spi-feedback-delay = <1>;
			samsung,spi-chip-select-mode = <0>;
			cs-clock-delay = <2>;
		};
	};
};

/*
 * CS35L41 speaker amplifiers on SPI13 (USI13). Pin assignments taken from
 * the vendor kernel (gs101-raviole-audio.dtsi). This only gets the amps to
 * probe on the SPI bus; there is no DAI link or sound card yet, so it does
 * not produce audio on its own.
 */
&pinctrl_gpio_alive {
	cs35l41_r_irq: cs35l41-r-irq-pins {
		samsung,pins = "gpa9-6"; /* XEINT_26 */
		samsung,pin-function = <GS101_PIN_FUNC_EINT>;
		samsung,pin-pud = <GS101_PIN_PULL_NONE>;
	};
};

&pinctrl_far_alive {
	cs35l41_l_irq: cs35l41-l-irq-pins {
		samsung,pins = "gpa6-3"; /* XEINT_3 */
		samsung,pin-function = <GS101_PIN_FUNC_EINT>;
		samsung,pin-pud = <GS101_PIN_PULL_NONE>;
	};
};

&pinctrl_peric0 {
	cs35l41_l_rst: cs35l41-l-rst-pins {
		samsung,pins = "gpp16-3"; /* XAPC_USI8_CTSN_CSN */
		samsung,pin-function = <GS101_PIN_FUNC_OUTPUT>;
		samsung,pin-pud = <GS101_PIN_PULL_NONE>;
	};

	cs35l41_cs2: cs35l41-cs2-pins {
		samsung,pins = "gpp1-0"; /* XAPC_GPIO2 */
		samsung,pin-function = <GS101_PIN_FUNC_OUTPUT>;
		samsung,pin-pud = <GS101_PIN_PULL_NONE>;
	};
};

&pinctrl_peric1 {
	cs35l41_r_rst: cs35l41-r-rst-pins {
		samsung,pins = "gpp23-7"; /* XAPC_USI12_CTSN_CSN */
		samsung,pin-function = <GS101_PIN_FUNC_OUTPUT>;
		samsung,pin-pud = <GS101_PIN_PULL_NONE>;
	};
};

&spi_13 {
	#address-cells = <1>;
	#size-cells = <0>;

	pinctrl-names = "default";
	pinctrl-0 = <&spi13_bus>, <&spi13_cs>, <&cs35l41_cs2>;

	/* Both chip selects are driven as GPIOs, so gpp25-3 uses spi13_cs
	 * (output function) rather than spi13_cs_func (SPI function).
	 */
	cs-gpios = <&gpp25 3 GPIO_ACTIVE_LOW>, <&gpp1 0 GPIO_ACTIVE_LOW>;
	num-cs = <2>;

	cs35l41_l: speaker-amp@0 {
		compatible = "cirrus,cs35l41dna";
		reg = <0>;
		#sound-dai-cells = <1>;
		cirrus,subsystem-id = "oriole";
		spi-max-frequency = <25000000>;
		/* Left amp: default (no prefix); vendor sets tuning-has-prefix. */
		cirrus,tuning-has-prefix;

		pinctrl-names = "default";
		pinctrl-0 = <&cs35l41_l_irq>, <&cs35l41_l_rst>;

		interrupt-parent = <&gpa6>;
		/*
		 * IRQ_TYPE_NONE, not LEVEL_LOW. The cs35l41 driver sets the
		 * trigger polarity itself from the GPIO2 config (irq_pol =
		 * IRQF_TRIGGER_LOW in cs35l41_gpio_config). Pinning a concrete
		 * type here makes the fwspec mapping fail with "type mismatch,
		 * failed to map hwirq-3" when the module is (re)loaded after boot
		 * -- the type is not cleaned up on free_irq, so the second map
		 * conflicts and spi->irq becomes 0 (request_irq(0) -> -EINVAL).
		 * The vendor uses type 0 here for the same reason.
		 */
		interrupts = <3 IRQ_TYPE_NONE>;
		reset-gpios = <&gpp16 3 GPIO_ACTIVE_HIGH>;

		VA-supply = <&s2mpg11_bucka>;
		VP-supply = <&V_SYS_dummy>;

		cirrus,boost-peak-milliamp = <3500>;
		cirrus,boost-ind-nanohenry = <1000>;
		cirrus,boost-cap-microfarad = <30>;
		cirrus,asp-sdout-hiz = <3>;
		/*
		 * vendor parity. NOTE: mainline's cs35l41 driver does NOT
		 * parse hw-noise-gate-select (no-op here, kept for parity).
		 * cirrus,hibernate-enable REMOVED: the Sep-6 build that played
		 * did NOT have it, and on gs101 the halo DSP mailbox wake fails
		 * (latches runtime_error, storms the IRQ) -- hibernate events
		 * spam every playback prepare. Matches the working build.
		 */
		cirrus,hw-noise-gate-select = <63>;

		/*
		 * Drive the interrupt out of GPIO2 (open-drain INT), which the
		 * interrupts property above listens to. The cs35l41dna driver
		 * parses this ONLY from a cirrus,gpio-config2 child node
		 * (of_get_child_by_name, cs35l41.c:3637) -- the flat
		 * cirrus,gpio2-* form was silently ignored. src-select = 0x4
		 * per vendor (all devices: ripcurrentpro/akita/caimito).
		 */
		cirrus,gpio-config2 {
			cirrus,gpio-src-select = <0x4>;
			cirrus,gpio-output-enable;
		};

		controller-data {
			/*
			 * Compensate the MISO round trip. spi-s3c64xx writes
			 * FB_CLK on every message and leaves it at 0 when this
			 * node is absent, which is too tight for reads at the
			 * 25 MHz the vendor runs these amps at.
			 */
			samsung,spi-feedback-delay = <1>;
			/* vendor parity (s3c64xx doesn't parse this) */
			samsung,spi-chip-select-mode = <1>;
		};
	};

	cs35l41_r: speaker-amp@1 {
		compatible = "cirrus,cs35l41dna";
		reg = <1>;
		#sound-dai-cells = <1>;
		cirrus,subsystem-id = "oriole";
		spi-max-frequency = <25000000>;
		/*
		 * "R" prefix comes from the aoc codec_cfg node below (this
		 * helped on mainline); no sound-name-prefix here, to avoid a
		 * double "RR". Tuning files carry the prefix; left amp default.
		 */
		cirrus,tuning-has-prefix;

		pinctrl-names = "default";
		pinctrl-0 = <&cs35l41_r_irq>, <&cs35l41_r_rst>;

		interrupt-parent = <&gpa9>;
		/* IRQ_TYPE_NONE: driver sets polarity; see cs35l41_l above. */
		interrupts = <6 IRQ_TYPE_NONE>;
		reset-gpios = <&gpp23 7 GPIO_ACTIVE_HIGH>;

		VA-supply = <&s2mpg11_bucka>;
		VP-supply = <&V_SYS_dummy>;

		cirrus,boost-peak-milliamp = <3500>;
		cirrus,boost-ind-nanohenry = <1000>;
		cirrus,boost-cap-microfarad = <30>;
		cirrus,asp-sdout-hiz = <3>;
		/*
		 * vendor parity (mainline driver doesn't parse these two -
		 * no-ops, kept for parity). hibernate-enable REMOVED to match
		 * the Sep-6 build that played; see cs35l41_l.
		 */
		cirrus,hw-noise-gate-select = <63>;
		cirrus,right-channel-amp;

		/*
		 * Drive the interrupt out of GPIO2 (open-drain INT), which the
		 * interrupts property above listens to. The cs35l41dna driver
		 * parses this ONLY from a cirrus,gpio-config2 child node
		 * (of_get_child_by_name, cs35l41.c:3637) -- the flat
		 * cirrus,gpio2-* form was silently ignored. src-select = 0x4
		 * per vendor (all devices: ripcurrentpro/akita/caimito).
		 */
		cirrus,gpio-config2 {
			cirrus,gpio-src-select = <0x4>;
			cirrus,gpio-output-enable;
		};

		controller-data {
			samsung,spi-feedback-delay = <1>;
			/* vendor: automatic SPI CS */
			samsung,spi-chip-select-mode = <1>;
		};
	};
};

&dai_be_tdm0_rx {
	codec {
		sound-dai = <&cs35l41_l 0>, <&cs35l41_r 0>;
	};
};

&dai_be_tdm0_tx {
	codec {
		sound-dai = <&cs35l41_l 0>, <&cs35l41_r 0>;
	};
};

&aoc_snd_card {
	clks {
		sys {
			sys@cs35l41_l {
				comp = <&cs35l41_l>;
				src = "BCLK";
				id = <0>;
				srcid = <0>;
				in_mul = <1>;
				out_mul = <1>;
			};

			sys@cs35l41_r {
				comp = <&cs35l41_r>;
				src = "BCLK";
				id = <0>;
				srcid = <0>;
				in_mul = <1>;
				out_mul = <1>;
			};
		};
	};

	/*
	 * Give the right cs35l41 the "R" name-prefix via the aoc card's
	 * codec_conf path (aoc_of_parse_codec_conf reads of_node + prefix).
	 * This is what actually applied the prefix on mainline; without it the
	 * card logs "can't find codec cfg node". sound-name-prefix is NOT set
	 * on cs35l41_r, so the prefix is applied once (no "RR"). Left amp stays
	 * default; both carry cirrus,tuning-has-prefix.
	 */
	codec_cfg {
		cs35l41_r_cfg {
			of_node = <&cs35l41_r>;
			prefix = "R";
		};
	};
};

/*
 * AoC drives the sensor rails. Without the list it logs "unsupported sensor
 * power list" and leaves them alone; the vendor names the same two LDOs in
 * gs101-common.dtsi.
 */
&aoc {
	sensor_1v8-supply = <&s2mpg11_ldo7s>;
	sensor_3v3-supply = <&s2mpg11_ldo6s>;
	sensor_power_list = "sensor_1v8", "sensor_3v3";

	/*
	 * DMIC/PDM rail (ldo20m "vddq_aoc_pdm"). Let AoC manage it so the
	 * SPEECH/hotword mic setup has power. NOTE: ldo20m is regulator-always-on
	 * + ext-control (EN2), so this may be redundant; if it also feeds memory
	 * the exclusive get will fail ("failed to get dmic regulator").
	 */
	dmic-supply = <&s2mpg10_ldo20m>;
	dmic_power_list = "dmic";
};

/*
 * GNSS: Broadcom BCM4775 on SPI5.
 *
 * A discrete receiver, not the integrated Kepler GNSS that arrives with zuma
 * -- which is why fw_data[GnssType] stays 0 on this SoC. Ported from the
 * vendor's gs101-common-gps.dtsi plus gs101-slider2-gps.dtsi, which is the
 * pin set gs101-raviole.dtsi pulls in for oriole and raven.
 *
 * The vendor also sets dma-mode, a pdma0 channel pair and swap-mode on the
 * controller. Those are properties of its own SPI driver; mainline's
 * spi-s3c64xx has no equivalent, so the transfers run PIO here.
 */
&usi5 {
	samsung,mode = <USI_MODE_SPI>;
	status = "okay";
};

&spi_5 {
	#address-cells = <1>;
	#size-cells = <0>;
	pinctrl-names = "default";
	pinctrl-0 = <&spi5_bus>, <&spi5_cs_func>;
	status = "okay";

	gnss: bcm4775@0 {
		compatible = "ssp-spi,bcm4775";
		reg = <0>;
		spi-max-frequency = <26000000>;
		spi-cpol;
		spi-cpha;

		pinctrl-names = "default";
		pinctrl-0 = <&gps_host_req>, <&gps_mcu_req>,
			    <&gps_mcu_resp>, <&gps_nstandby>;

		host-req-gpios = <&gpa6 4 GPIO_ACTIVE_HIGH>;
		mcu-req-gpios = <&gpp1 1 GPIO_ACTIVE_HIGH>;
		mcu-resp-gpios = <&gpp0 0 GPIO_ACTIVE_HIGH>;
		nstandby-gpios = <&gpp0 2 GPIO_ACTIVE_LOW>;

		controller-data {
			samsung,spi-feedback-delay = <1>;
		};
	};
};

/ {
	/* 1PPS output from the receiver. */
	bbd_pps {
		compatible = "bbd-pps-gpio";
		gpios = <&gpp17 1 GPIO_ACTIVE_HIGH>;
		/*
		 * assert-falling-edge is read with
		 * device_property_read_bool(), so a present property is true
		 * whatever its value. The vendor writes "= <0>" meaning "no",
		 * which reads as yes; leaving it out is how you say no.
		 */
		status = "okay";
	};
};

&pinctrl_far_alive {
	gps_host_req: gps-host-req-pins {
		samsung,pins = "gpa6-4";
		samsung,pin-function = <GS101_PIN_FUNC_EINT>;
		samsung,pin-pud = <GS101_PIN_PULL_NONE>;
	};
};

&pinctrl_peric0 {
	gps_mcu_req: gps-mcu-req-pins {
		samsung,pins = "gpp1-1";
		samsung,pin-function = <GS101_PIN_FUNC_OUTPUT>;
		samsung,pin-pud = <GS101_PIN_PULL_NONE>;
	};

	gps_mcu_resp: gps-mcu-resp-pins {
		samsung,pins = "gpp0-0";
		samsung,pin-function = <GS101_PIN_FUNC_INPUT>;
		samsung,pin-pud = <GS101_PIN_PULL_DOWN>;
	};

	gps_nstandby: gps-nstandby-pins {
		samsung,pins = "gpp0-2";
		samsung,pin-function = <GS101_PIN_FUNC_OUTPUT>;
		samsung,pin-pud = <GS101_PIN_PULL_NONE>;
	};

	/*
	 * Front camera (IMX355) master clock uses the existing sensor_mclk2_fn
	 * pinmux (gpp5-0 func 2) already defined in gs101-pinctrl.dtsi.
	 */
};

/*
 * BCM4389 WLAN on PCIe HSI2 (channel 1): powered by the always-on
 * wlan_pwrseq regulator (vpcie-supply on pcie1 in gs101.dtsi). No bcmdhd
 * DT node on purpose -- with one, bcmdhd owns wl_reg_on and runs its
 * power-cycle recovery (secondary bus reset), which on this mainline setup
 * knocks the endpoint off the bus (VID 0xffffffff) and never recovers.
 * Without a node bcmdhd assumes an always-on regulator and brings the
 * already-enumerated endpoint up cleanly -- the state that works on cold
 * boot. (This is why adding a node for kexec survival regressed cold boot.)
 */

/*
 * Front camera: Sony IMX355 on HSI2C bus 2 (@0x1a). M1 = probe + chip-ID over
 * I2C (proves slg51000 rails + clock + reset). Master clock is CIS_CLK1 out of
 * CMU_TOP at 24.576 MHz (gs101 has no 19.2 MHz; imx355 driver patched to accept
 * it). reset is active-low in hardware (pin high = run); the mainline driver
 * asserts logical-1 for reset, so declare GPIO_ACTIVE_LOW.
 * CSIS endpoint is wired up in M2.
 */
/* Enable the USI2 wrapper in I2C mode so hsi2c_2 (front camera bus) comes up. */
&usi2 {
	samsung,mode = <USI_MODE_I2C>;
	status = "okay";
};

&hsi2c_2 {
	status = "okay";

	imx355: camera-sensor@1a {
		compatible = "sony,imx355";
		/* Front camera: libcamera Location/Transform (was missing -> "Failed to retrieve the camera location"). */
		orientation = <0>;
		rotation = <270>;	/* sensor mounted rotated 270 deg (user-observed 2026-09-20) */
		reg = <0x1a>;

		/*
		 * Sensor mclk = the final CIS_CLK1 output, which is the divider
		 * (DOUT), not the gate (GOUT) that sits before it. Consuming DOUT
		 * makes imx355 read the true rate and enabling it propagates up
		 * through the gate. mux default parent is oscclk (24.576 MHz), so
		 * the divider resolves to /1. If the CMU cannot honour this, imx355
		 * probe prints the actual rate ("external clock N is not supported").
		 */
		clocks = <&cmu_top CLK_DOUT_CMU_CIS_CLK1>;
		/*
		 * Vendor (gs101-oriole-camera.dtsi) runs the imx355 INCK from
		 * CIS_CLK1 at a requested 24000000 Hz with the sensor's 24 MHz
		 * PLL tables, not from the raw 24.576 MHz oscillator. No shared
		 * PLL tap divides to exactly 24 MHz; parent shared2/2 = 400 MHz
		 * gives 400/17 = 23.53 MHz, which the sensor tolerates (the driver
		 * matches the 24 MHz table within 5%).
		 * 2026-09-21: exact 24 MHz via the otherwise unused spare PLL,
		 * programmed to 768 MHz (rate table in clk-gs101.c), divider /32.
		 */
		assigned-clocks = <&cmu_top CLK_FOUT_SPARE_PLL>,
				  <&cmu_top CLK_MOUT_CMU_CIS_CLK1>,
				  <&cmu_top CLK_DOUT_CMU_CIS_CLK1>;
		assigned-clock-parents = <0>,
					 <&cmu_top CLK_FOUT_SPARE_PLL>;
		assigned-clock-rates = <768000000>, <0>, <24000000>;

		reset-gpios = <&gpp4 2 GPIO_ACTIVE_LOW>;

		/*
		 * KNOWN-GOOD rails (imx355 binds on I2C with these). The
		 * production LWIS "ldo1 + ldo_dummy" model does NOT translate to
		 * the mainline regulator model: dvdd/dovdd physically come from the
		 * real SLG LDOs (ldo6/ldo7), not hardwired board rails, so pointing
		 * them at fixed cam_dvdd/cam_dovdd (software no-ops) drops physical
		 * dvdd/dovdd -> sensor unpowered -> -EIO on the chip-id read.
		 */
		avdd-supply = <&slg51000_ldo3>;		/* 2.8 V */
		dvdd-supply = <&slg51000_ldo6>;		/* 1.2 V */
		dovdd-supply = <&slg51000_ldo7>;	/* 1.8 V */

		pinctrl-names = "default";
		pinctrl-0 = <&sensor_mclk2_fn>;

		port {
			imx355_ep: endpoint {
				remote-endpoint = <&csis_sink>;
				data-lanes = <1 2 3 4>;
				link-frequencies = /bits/ 64 <360000000>;
			};
		};
	};

	/*
	 * Front camera module EEPROM (m24c64s), same board as the IMX355 and
	 * powered by the same avdd rail (slg51000_ldo1) but needing no mclk or
	 * reset. Used as a canary: if at24 reads this, avdd + the bus + the slg
	 * LDO1 output are all good, and the IMX355 -EIO is sensor-specific
	 * (dvdd/mclk). If this also fails, the slg power-up (avdd) is the fault.
	 */
	cam_front_eeprom: eeprom@51 {
		compatible = "atmel,24c64";
		reg = <0x51>;
		vcc-supply = <&slg51000_ldo1>;
	};
};

/* Enable the USI1 wrapper in I2C mode so hsi2c_1 (rear main camera bus) comes up. */
&usi1 {
	samsung,mode = <USI_MODE_I2C>;
	status = "okay";
};

/*
 * Rear main camera: Samsung S5KGN1 on HSI2C bus 1 (@0x3d), 4-lane MIPI,
 * CIS_CLK3 on sensor_mclk4, reset gpp2-2. Rails and enables from the vendor
 * DT (gs101-oriole-camera.dtsi + proto1 overlay): ldo1 avdd, ldo4 dvdd,
 * ldo7 dovdd, SLG51000 GPIO 2/0/1 as "enable"/"shared-enable1/2".
 */
&hsi2c_1 {
	status = "okay";

	s5kgn1: camera-sensor@3d {
		compatible = "samsung,s5kgn1";
		orientation = <1>;
		rotation = <90>;
		reg = <0x3d>;

		clocks = <&cmu_top CLK_DOUT_CMU_CIS_CLK3>;
		/* exact 24 MHz from the spare PLL at 768 MHz, divider /32 (see imx355). */
		assigned-clocks = <&cmu_top CLK_FOUT_SPARE_PLL>,
				  <&cmu_top CLK_MOUT_CMU_CIS_CLK3>,
				  <&cmu_top CLK_DOUT_CMU_CIS_CLK3>;
		assigned-clock-parents = <0>,
					 <&cmu_top CLK_FOUT_SPARE_PLL>;
		assigned-clock-rates = <768000000>, <0>, <24000000>;

		reset-gpios = <&gpp2 2 GPIO_ACTIVE_LOW>;
		enable-gpios = <&slg51000 2 GPIO_ACTIVE_HIGH>,
			       <&slg51000 0 GPIO_ACTIVE_HIGH>,
			       <&slg51000 1 GPIO_ACTIVE_HIGH>;

		/*
		 * 2026-09-21: the production SLG51000 OTP routes the enable bits
		 * through its mux array (0x1715..0x171b read 03 05 2c 04 05 2d 02):
		 * framework "ldo1" (bit0) -> physical LDO7 1.8 V, "ldo2" (bit1) ->
		 * LDO1 2.8 V, "ldo3" (bit2) -> LDO4 2.9 V, "ldo4" (bit3) -> LDO2 +
		 * LDO5, "ldo5" (bit4) -> LUT -> LDO6, "ldo7" (bit6) -> GPIO4.
		 * Vendor production GN1 = ldo1 + ldo2 + ldo3. With ldo1/ldo4/ldo7
		 * (proto1 names) the sensor had no 2.8/2.9 V rail and died at
		 * stream-on; with bits 1+2 forced on it streams (runtime test).
		 */
		/* avdd-supply = <&slg51000_ldo1>; */
		/* dvdd-supply = <&slg51000_ldo4>; */
		/* dovdd-supply = <&slg51000_ldo7>; */
		avdd-supply = <&slg51000_ldo2>;		/* bit1 -> LDO1 2.8 V */
		dvdd-supply = <&slg51000_ldo3>;		/* bit2 -> LDO4 2.9 V (production "ldo3"; not a core rail) */
		dovdd-supply = <&slg51000_ldo1>;	/* bit0 -> LDO7 1.8 V */

		pinctrl-names = "default";
		pinctrl-0 = <&sensor_mclk4_fn>;

		port {
			s5kgn1_ep: endpoint {
				remote-endpoint = <&csis1_sink>;
				bus-type = <MEDIA_BUS_TYPE_CSI2_CPHY>;	/* C-PHY, see csis1_sink */
				data-lanes = <1 2 3>;
				link-frequencies = /bits/ 64 <798000000>;
			};
		};
	};
};

/* Enable the USI3 wrapper in I2C mode so hsi2c_3 (rear camera bus) comes up. */
&usi3 {
	samsung,mode = <USI_MODE_I2C>;
	status = "okay";
};

/*
 * Rear ultra-wide camera: Sony IMX386 on HSI2C bus 3 (@0x1a). 2-lane MIPI,
 * CIS_CLK0 on sensor_mclk1 (gpp3-0). Proto1 rails: avdd=ldo2, dvdd=ldo5,
 * dovdd=ldo7 (shared with IMX355). reset gpp6-3 (active-low in the driver).
 */
&hsi2c_3 {
	status = "okay";

	imx386: camera-sensor@1a {
		compatible = "sony,imx386";
		/* Rear ultra-wide: libcamera Location = back. */
		orientation = <1>;
		rotation = <90>;	/* user-observed after the 0x1e repack (2026-09-20) */
		reg = <0x1a>;

		clocks = <&cmu_top CLK_DOUT_CMU_CIS_CLK0>;
		/* Vendor: CIS_CLK0 requested at 24000000 (24 MHz sensor tables); see imx355. */
		/* 2026-09-21: exact 24 MHz from the spare PLL at 768 MHz, divider /32. */
		assigned-clocks = <&cmu_top CLK_FOUT_SPARE_PLL>,
				  <&cmu_top CLK_MOUT_CMU_CIS_CLK0>,
				  <&cmu_top CLK_DOUT_CMU_CIS_CLK0>;
		assigned-clock-parents = <0>,
					 <&cmu_top CLK_FOUT_SPARE_PLL>;
		assigned-clock-rates = <768000000>, <0>, <24000000>;

		reset-gpios = <&gpp6 3 GPIO_ACTIVE_LOW>;

		/* KNOWN-GOOD proto1-style rails (real SLG LDOs, like imx355). */
		avdd-supply = <&slg51000_ldo2>;
		dvdd-supply = <&slg51000_ldo5>;
		dovdd-supply = <&slg51000_ldo7>;

		pinctrl-names = "default";
		pinctrl-0 = <&sensor_mclk1_fn>;

		port {
			imx386_ep: endpoint {
				remote-endpoint = <&csis2_sink>;
				data-lanes = <1 2>;	/* imx386 is 2-lane; 4 corrupts the frame (2026-09-19) */
				link-frequencies = /bits/ 64 <360000000>;
			};
		};
	};
};
